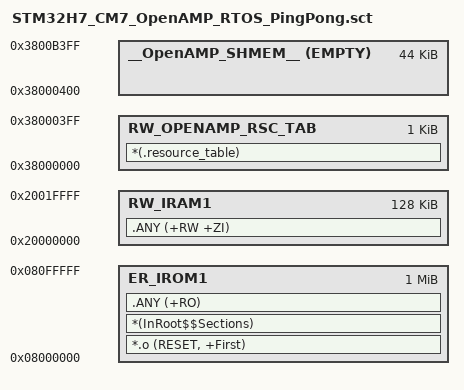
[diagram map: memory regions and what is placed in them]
; *************************************************************
; *** Scatter-Loading Description File generated by uVision ***
; *************************************************************

LR_IROM1 0x08000000 0x00100000  {    ; load region size_region
  ER_IROM1 0x08000000 0x00100000  {  ; load address = execution address
   *.o (RESET, +First)
   *(InRoot$$Sections)
   .ANY (+RO)
  }
  RW_IRAM1 0x20000000 0x00020000  {  ; RW data
   .ANY (+RW +ZI)
  }
   
  RW_OPENAMP_RSC_TAB 0x38000000 0x00000400 { ; resource_table area
  *(.resource_table)
  }
  
  __OpenAMP_SHMEM__ 0x38000400  EMPTY 0x0000B000 {} ; Shared Memory area used by OpenAMP
}

